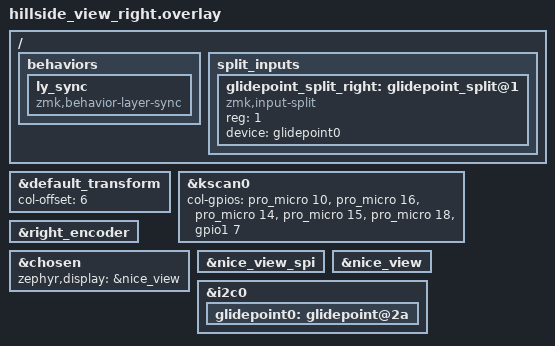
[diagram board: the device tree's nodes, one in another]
/*
 * Copyright (c) 2022 The ZMK Contributors
 *
 * SPDX-License-Identifier: MIT
 */

#include "hillside_view.dtsi"
#include <input/processors.dtsi>
#include <dt-bindings/zmk/input_transform.h>

&default_transform {
  col-offset = <6>;
};

&kscan0 {
  col-gpios
    = <&pro_micro 10 GPIO_ACTIVE_HIGH>
    , <&pro_micro 16 GPIO_ACTIVE_HIGH>
    , <&pro_micro 14 GPIO_ACTIVE_HIGH>
    , <&pro_micro 15 GPIO_ACTIVE_HIGH>
    , <&pro_micro 18 GPIO_ACTIVE_HIGH>
    , <&gpio1 7 GPIO_ACTIVE_HIGH>
    ;
};

&right_encoder {
  status = "okay";
};

&chosen {
  zephyr,display = &nice_view;
};

&nice_view_spi {
  status = "okay";
};

&nice_view {
  status = "okay";
};

&i2c0 {
    status = "okay";
    glidepoint0: glidepoint@2a {
        status = "okay";
    };
};

/ {
    behaviors {
        ly_sync: ly_sync {
            compatible = "zmk,behavior-layer-sync";
            #binding-cells = <0>;
        };
    };

    /* Native ZMK split input support - peripheral sends physical glidepoint to central */
    split_inputs {
        #address-cells = <1>;
        #size-cells = <0>;

        glidepoint_split_right: glidepoint_split@1 {
            compatible = "zmk,input-split";
            reg = <1>; /* Must match central's glidepoint_right reg value */
            device = <&glidepoint0>; /* Physical Cirque glidepoint */
        };
    };
};
